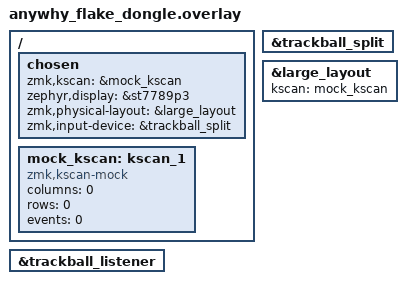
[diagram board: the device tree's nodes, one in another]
#include "anywhy_flake.dtsi"
#include "anywhy_flake_split_input.dtsi"

&trackball_split {
  status = "okay";
};

/* enable the listener on central */
&trackball_listener {
  status = "okay";
};

/ {
    chosen {
        zmk,kscan = &mock_kscan;
        /* The st7789p3 node itself — pinctrl, &spi0, and the display's
         * timing/pin properties — is owned by pacman_adapter.overlay,
         * which this dongle always builds alongside (see build.yaml).
         * It used to be duplicated here too, byte-for-byte; two sources
         * of truth for the same SPI pins meant every polarity/offset fix
         * had to land twice. zephyr,display (not the non-standard
         * zmk,display) is what ZMK's display subsystem actually reads. */
        zephyr,display = &st7789p3;
        zmk,physical-layout = &large_layout;
        zmk,input-device    = &trackball_split;
    };

    mock_kscan: kscan_1 {
        compatible = "zmk,kscan-mock";
        columns = <0>;
        rows = <0>;
        events = <0>;
    };

};

&large_layout {
        kscan = <&mock_kscan>;
};
